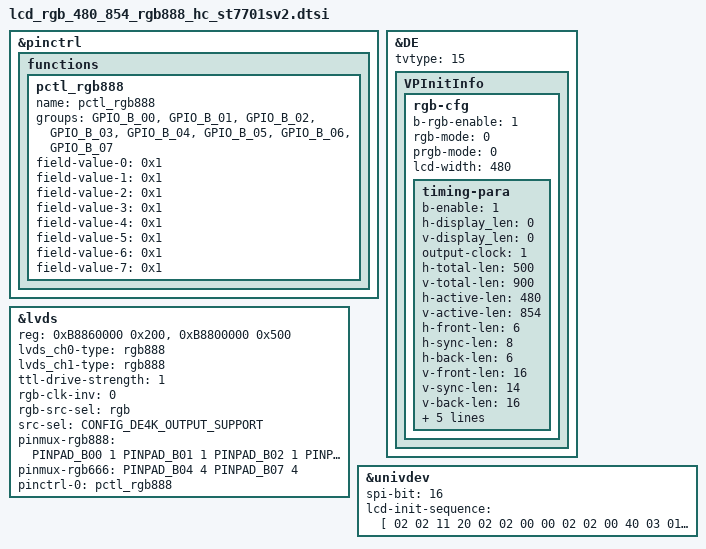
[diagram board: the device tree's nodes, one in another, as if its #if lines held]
&pinctrl {
	functions {
		pctl_rgb888: pctl_rgb888 {
			name = "pctl_rgb888";
			groups = "GPIO_B_00", "GPIO_B_01", "GPIO_B_02", "GPIO_B_03", "GPIO_B_04", "GPIO_B_05", "GPIO_B_06", "GPIO_B_07";
			field-value-0 = <0x1>;
			field-value-1 = <0x1>;
			field-value-2 = <0x1>;
			field-value-3 = <0x1>;
			field-value-4 = <0x1>;
			field-value-5 = <0x1>;
			field-value-6 = <0x1>;
			field-value-7 = <0x1>;
		};
	};
};

&lvds {
	reg = <0xB8860000 0x200>, <0xB8800000 0x500>;
	/*
	 * "lvds"		: LVDS screen
	 * "rgb888" 	: RGB screen
	 * "rgb666" 	: RGB screen
	 * "rgb565" 	: RGB screen
	 * "i2so"		: I2S OUT
	 * "gpio"		: only GPIO out
	 */
	lvds_ch0-type = "rgb888";
	lvds_ch1-type = "rgb888";

	/*
	 * 0: LVDS_TTL_DRIVE_STRENGTH_WEAKEST,
	 * 1: LVDS_TTL_DRIVE_STRENGTH_NORMAL,
	 * 2: LVDS_TTL_DRIVE_STRENGTH_ENHANCE,
	 * 3: LVDS_TTL_DRIVE_STRENGTH_STRONGEST,
	 */
	ttl-drive-strength = <1>;

	/*
	 *0 : RGB CLOCK NO INVERSION
	 *1 : RGB CLOCK INVERSION
	 */
	rgb-clk-inv = <0>;

	/*
	 * rgb gbr bgr
	 * rbg grb brg
	 */
	rgb-src-sel = "rgb";

	/*
	 * 0: E_SRC_SEL_FXDE = 0
	 * 1: E_SRC_SEL_4KDE = 1
	 * 2: E_SRC_SEL_HDMI_RX = 2
	 * 3: E_SRC_SEL_FXDE_ = 3
	 * 4: E_SRC_2_SEL_FXDE_LOW_TO_HIGH = 4 //need clsoe pq
	 * 5: E_SRC_2_SEL_DE4K_LOW_TO_HIGH = 5 //need clsoe pq
	 * 6: E_SRC_2_SEL_HDMI_RX_LOW_TO_HIGH = 6 //need clsoe pq
	 * 7: E_SRC_2_SEL_PQ_LOW_TO_HIGH = 7
	 */
	src-sel = <CONFIG_DE4K_OUTPUT_SUPPORT>;

	pinmux-rgb888 = <PINPAD_B00 1 PINPAD_B01 1 PINPAD_B02 1 PINPAD_B03 1 PINPAD_B04 1 PINPAD_B05 1 PINPAD_B06 1 PINPAD_B07 1>;/*RGB888 other pin set*/
	pinmux-rgb666 = <PINPAD_B04 4 PINPAD_B07 4>; /*RGB666 other pin set*/
	pinctrl-names = "rgb888";
	pinctrl-0 = <&pctl_rgb888>;
	// status = "okay";
};

&DE {
	tvtype = <15>;
	VPInitInfo {
		rgb-cfg{
			b-rgb-enable = <1>;
			/*
			 * 0: MODE_PRGB
			 * 1: MODE_SRGB
			 */
			rgb-mode = <0>;
			/*
			 * 0: MODE_PRGB_888_10bit
			 * 1: MODE_PRGB_666
			 */
			prgb-mode = <0>;
			lcd-width = <480>;
			timing-para {
				/* bool type, 0 or 1*/
				b-enable = <1>;

				h-display_len = <0>;
				v-display_len = <0>;

				/*
				 * VPO_RGB_CLOCK_27M = 1,
				 * VPO_RGB_CLOCK_33M = 2,
				 * VPO_RGB_CLOCK_49M = 3,
				 * VPO_RGB_CLOCK_66M = 4,
				 * VPO_RGB_CLOCK_74M = 5,
				 * VPO_RGB_CLOCK_85M = 6,
				 * VPO_RGB_CLOCK_108M = 7,
				 * VPO_RGB_CLOCK_6_6M = 8,
				 * VPO_RGB_CLOCK_9M = 9,
				 * VPO_RGB_CLOCK_39_6M = 10,
				 * VPO_RGB_CLOCK_74_25M = 11,
				 * VPO_RGB_CLOCK_148_5M = 12,
				 * VPO_RGB_CLOCK_54M = 13,
				 * VPO_RGB_CLOCK_132M = 14,//H1600
				 * VPO_RGB_CLOCK_297M = 15,//H1600 only De4k
				 * VPO_RGB_CLOCK_DPLL = 0xFF,//H1600
				*/
				output-clock = <1>;

				h-total-len = <500>;
				v-total-len = <900>;

				h-active-len = <480>;
				v-active-len = <854>;

				h-front-len = <6>;
				h-sync-len = <8>;
				h-back-len = <6>;

				v-front-len = <16>;
				v-sync-len = <14>;
				v-back-len = <16>;

				/* bool type, 0 or 1*/
				h-sync-level = <0>;
				/* bool type, 0 or 1*/
				v-sync-level = <0>;

				/* bool type, 0 or 1*/
				active-polarity = <1>;
				frame-rate = <60000>;

				/*
				31	De_dig_pll_en
				25:16	DE_DIG_PLL_M_ctrl
				13:8	DE_DIG_PLL_N_ctrl
				5:0	DE_DIG_PLL_L_ctrl
				de_digpll_clock = 24 *(M+1)/((N+1)*(L+1))
				*/
				dpll-clock-reg-value = <0x0>;
			};
		};
	};
};

#ifdef LCD_UNIVDEV_ENABLED
&univdev{
	spi-bit = <16>;
	lcd-init-sequence = [
		02 02 11 20
		02 02 00 00
		02 02 00 40
		03 01 01
		02 02 ff 20
		02 02 00 00
		02 02 77 40
		02 02 ff 20
		02 02 01 00
		02 02 01 40
		02 02 ff 20
		02 02 02 00
		02 02 00 40
		02 02 ff 20
		02 02 03 00
		02 02 00 40
		02 02 ff 20
		02 02 04 00
		02 02 10 40
		02 02 c0 20
		02 02 00 00
		02 02 e9 40
		02 02 c0 20
		02 02 01 00
		02 02 03 40
		02 02 c1 20
		02 02 00 00
		02 02 0c 40
		02 02 c1 20
		02 02 01 00
		02 02 02 40
		02 02 c2 20
		02 02 00 00
		02 02 10 40
		02 02 c2 20
		02 02 01 00
		02 02 06 40
		02 02 cc 20
		02 02 00 00
		02 02 38 40
		02 02 b0 20
		02 02 00 00
		02 02 40 40
		02 02 b0 20
		02 02 01 00
		02 02 0b 40
		02 02 b0 20
		02 02 02 00
		02 02 58 40
		02 02 b0 20
		02 02 03 00
		02 02 0c 40
		02 02 b0 20
		02 02 04 00
		02 02 11 40
		02 02 b0 20
		02 02 05 00
		02 02 06 40
		02 02 b0 20
		02 02 06 00
		02 02 0b 40
		02 02 b0 20
		02 02 07 00
		02 02 08 40
		02 02 b0 20
		02 02 08 00
		02 02 09 40
		02 02 b0 20
		02 02 09 00
		02 02 26 40
		02 02 b0 20
		02 02 0a 00
		02 02 06 40
		02 02 b0 20
		02 02 0b 00
		02 02 15 40
		02 02 b0 20
		02 02 0c 00
		02 02 18 40
		02 02 b0 20
		02 02 0d 00
		02 02 6a 40
		02 02 b0 20
		02 02 0e 00
		02 02 6e 40
		02 02 b0 20
		02 02 0f 00
		02 02 4f 40
		02 02 b1 20
		02 02 00 00
		02 02 40 40
		02 02 b1 20
		02 02 01 00
		02 02 11 40
		02 02 b1 20
		02 02 02 00
		02 02 57 40
		02 02 b1 20
		02 02 03 00
		02 02 0d 40
		02 02 b1 20
		02 02 04 00
		02 02 11 40
		02 02 b1 20
		02 02 05 00
		02 02 07 40
		02 02 b1 20
		02 02 06 00
		02 02 0b 40
		02 02 b1 20
		02 02 07 00
		02 02 09 40
		02 02 b1 20
		02 02 08 00
		02 02 08 40
		02 02 b1 20
		02 02 09 00
		02 02 26 40
		02 02 b1 20
		02 02 0a 00
		02 02 05 40
		02 02 b1 20
		02 02 0b 00
		02 02 d3 40
		02 02 b1 20
		02 02 0c 00
		02 02 0d 40
		02 02 b1 20
		02 02 0d 00
		02 02 6b 40
		02 02 b1 20
		02 02 0e 00
		02 02 6e 40
		02 02 b1 20
		02 02 0f 00
		02 02 4f 40
		02 02 ff 20
		02 02 00 00
		02 02 77 40
		02 02 ff 20
		02 02 01 00
		02 02 01 40
		02 02 ff 20
		02 02 02 00
		02 02 00 40
		02 02 ff 20
		02 02 03 00
		02 02 00 40
		02 02 ff 20
		02 02 04 00
		02 02 11 40
		02 02 b0 20
		02 02 00 00
		02 02 56 40
		02 02 b1 20
		02 02 00 00
		02 02 3a 40
		02 02 b2 20
		02 02 00 00
		02 02 87 40
		02 02 b3 20
		02 02 00 00
		02 02 80 40
		02 02 b5 20
		02 02 00 00
		02 02 4d 40
		02 02 b7 20
		02 02 00 00
		02 02 85 40
		02 02 b8 20
		02 02 00 00
		02 02 10 40
		02 02 b9 20
		02 02 00 00
		02 02 10 40
		02 02 bc 20
		02 02 00 00
		02 02 03 40
		02 02 c0 20
		02 02 00 00
		02 02 89 40
		02 02 c1 20
		02 02 00 00
		02 02 78 40
		02 02 c2 20
		02 02 00 00
		02 02 78 40
		02 02 d0 20
		02 02 00 00
		02 02 88 40
		02 02 e0 20
		02 02 00 00
		02 02 00 40
		02 02 e0 20
		02 02 01 00
		02 02 00 40
		02 02 e0 20
		02 02 02 00
		02 02 02 40
		02 02 e1 20
		02 02 00 00
		02 02 04 40
		02 02 e1 20
		02 02 01 00
		02 02 00 40
		02 02 e1 20
		02 02 02 00
		02 02 00 40
		02 02 e1 20
		02 02 03 00
		02 02 00 40
		02 02 e1 20
		02 02 04 00
		02 02 05 40
		02 02 e1 20
		02 02 05 00
		02 02 00 40
		02 02 e1 20
		02 02 06 00
		02 02 00 40
		02 02 e1 20
		02 02 07 00
		02 02 00 40
		02 02 e1 20
		02 02 08 00
		02 02 00 40
		02 02 e1 20
		02 02 09 00
		02 02 20 40
		02 02 e1 20
		02 02 0a 00
		02 02 20 40
		02 02 e2 20
		02 02 00 00
		02 02 00 40
		02 02 e2 20
		02 02 01 00
		02 02 00 40
		02 02 e2 20
		02 02 02 00
		02 02 00 40
		02 02 e2 20
		02 02 03 00
		02 02 00 40
		02 02 e2 20
		02 02 04 00
		02 02 00 40
		02 02 e2 20
		02 02 05 00
		02 02 00 40
		02 02 e2 20
		02 02 06 00
		02 02 00 40
		02 02 e2 20
		02 02 07 00
		02 02 00 40
		02 02 e2 20
		02 02 08 00
		02 02 00 40
		02 02 e2 20
		02 02 09 00
		02 02 00 40
		02 02 e2 20
		02 02 0a 00
		02 02 00 40
		02 02 e2 20
		02 02 0b 00
		02 02 00 40
		02 02 e2 20
		02 02 0c 00
		02 02 00 40
		02 02 e3 20
		02 02 00 00
		02 02 00 40
		02 02 e3 20
		02 02 01 00
		02 02 00 40
		02 02 e3 20
		02 02 02 00
		02 02 33 40
		02 02 e3 20
		02 02 03 00
		02 02 00 40
		02 02 e4 20
		02 02 00 00
		02 02 22 40
		02 02 e4 20
		02 02 01 00
		02 02 00 40
		02 02 e5 20
		02 02 00 00
		02 02 04 40
		02 02 e5 20
		02 02 01 00
		02 02 5c 40
		02 02 e5 20
		02 02 02 00
		02 02 a0 40
		02 02 e5 20
		02 02 03 00
		02 02 a0 40
		02 02 e5 20
		02 02 04 00
		02 02 06 40
		02 02 e5 20
		02 02 05 00
		02 02 5c 40
		02 02 e5 20
		02 02 06 00
		02 02 a0 40
		02 02 e5 20
		02 02 07 00
		02 02 a0 40
		02 02 e5 20
		02 02 08 00
		02 02 00 40
		02 02 e5 20
		02 02 09 00
		02 02 00 40
		02 02 e5 20
		02 02 0a 00
		02 02 00 40
		02 02 e5 20
		02 02 0b 00
		02 02 00 40
		02 02 e5 20
		02 02 0c 00
		02 02 00 40
		02 02 e5 20
		02 02 0d 00
		02 02 00 40
		02 02 e5 20
		02 02 0e 00
		02 02 00 40
		02 02 e5 20
		02 02 0f 00
		02 02 00 40
		02 02 e6 20
		02 02 00 00
		02 02 00 40
		02 02 e6 20
		02 02 01 00
		02 02 00 40
		02 02 e6 20
		02 02 02 00
		02 02 33 40
		02 02 e6 20
		02 02 03 00
		02 02 00 40
		02 02 e7 20
		02 02 00 00
		02 02 22 40
		02 02 e7 20
		02 02 01 00
		02 02 00 40
		02 02 e8 20
		02 02 00 00
		02 02 05 40
		02 02 e8 20
		02 02 01 00
		02 02 5c 40
		02 02 e8 20
		02 02 02 00
		02 02 a0 40
		02 02 e8 20
		02 02 03 00
		02 02 a0 40
		02 02 e8 20
		02 02 04 00
		02 02 07 40
		02 02 e8 20
		02 02 05 00
		02 02 5c 40
		02 02 e8 20
		02 02 06 00
		02 02 a0 40
		02 02 e8 20
		02 02 07 00
		02 02 a0 40
		02 02 e8 20
		02 02 08 00
		02 02 00 40
		02 02 e8 20
		02 02 09 00
		02 02 00 40
		02 02 e8 20
		02 02 0a 00
		02 02 00 40
		02 02 e8 20
		02 02 0b 00
		02 02 00 40
		02 02 e8 20
		02 02 0c 00
		02 02 00 40
		02 02 e8 20
		02 02 0d 00
		02 02 00 40
		02 02 e8 20
		02 02 0e 00
		02 02 00 40
		02 02 e8 20
		02 02 0f 00
		02 02 00 40
		02 02 eb 20
		02 02 00 00
		02 02 02 40
		02 02 eb 20
		02 02 01 00
		02 02 00 40
		02 02 eb 20
		02 02 02 00
		02 02 40 40
		02 02 eb 20
		02 02 03 00
		02 02 40 40
		02 02 eb 20
		02 02 04 00
		02 02 00 40
		02 02 eb 20
		02 02 05 00
		02 02 00 40
		02 02 eb 20
		02 02 06 00
		02 02 00 40
		02 02 ec 20
		02 02 00 00
		02 02 00 40
		02 02 ec 20
		02 02 01 00
		02 02 00 40
		02 02 ed 20
		02 02 00 00
		02 02 fa 40
		02 02 ed 20
		02 02 01 00
		02 02 45 40
		02 02 ed 20
		02 02 02 00
		02 02 0b 40
		02 02 ed 20
		02 02 03 00
		02 02 ff 40
		02 02 ed 20
		02 02 04 00
		02 02 ff 40
		02 02 ed 20
		02 02 05 00
		02 02 ff 40
		02 02 ed 20
		02 02 06 00
		02 02 ff 40
		02 02 ed 20
		02 02 07 00
		02 02 ff 40
		02 02 ed 20
		02 02 08 00
		02 02 ff 40
		02 02 ed 20
		02 02 09 00
		02 02 ff 40
		02 02 ed 20
		02 02 0a 00
		02 02 ff 40
		02 02 ed 20
		02 02 0b 00
		02 02 ff 40
		02 02 ed 20
		02 02 0c 00
		02 02 ff 40
		02 02 ed 20
		02 02 0d 00
		02 02 b0 40
		02 02 ed 20
		02 02 0e 00
		02 02 54 40
		02 02 ed 20
		02 02 0f 00
		02 02 af 40
		02 02 ef 20
		02 02 00 00
		02 02 08 40
		02 02 ef 20
		02 02 01 00
		02 02 08 40
		02 02 ef 20
		02 02 02 00
		02 02 08 40
		02 02 ef 20
		02 02 03 00
		02 02 45 40
		02 02 ef 20
		02 02 04 00
		02 02 3f 40
		02 02 ef 20
		02 02 05 00
		02 02 54 40
		02 02 ff 20
		02 02 00 00
		02 02 77 40
		02 02 ff 20
		02 02 01 00
		02 02 01 40
		02 02 ff 20
		02 02 02 00
		02 02 00 40
		02 02 ff 20
		02 02 03 00
		02 02 00 40
		02 02 ff 20
		02 02 04 00
		02 02 00 40
		02 02 3a 20
		02 02 00 00
		02 02 70 40
		02 02 36 20
		02 02 00 00
		02 02 00 40
		02 02 20 20
		02 02 00 00
		02 02 00 40
		02 02 29 20
		02 02 00 00
		02 02 00 40
	];
};
#endif
